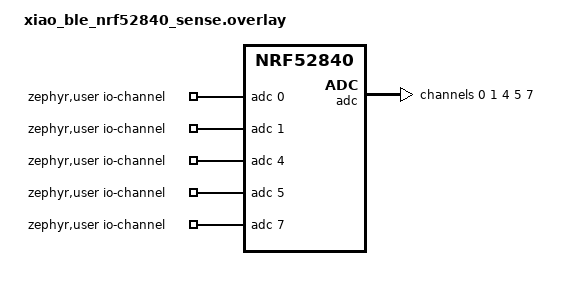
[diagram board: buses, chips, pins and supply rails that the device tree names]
/*
 * Copyright (c) 2025 NED KONZ <NED@METAMAGIX.TECH>
 *
 * SPDX-License-Identifier: Apache-2.0
 */

// Replace default on-chip flash with external flash
/delete-node/ &storage_partition;

// 16Mib (2MiB) flash, mount as /flash
&p25q16h {
	partitions {
		compatible = "fixed-partitions";
		#address-cells = <1>;
		#size-cells = <1>;

		storage_partition: partition@0 {
			label = "storage";
			reg = <0x00000000 0x200000>;
		};
	};
};

/ {
	zephyr,user {
		io-channels = <&adc 0>, <&adc 1>, <&adc 4>, <&adc 5>, <&adc 7>;
	};
};

&adc {
	#address-cells = <1>;
	#size-cells = <0>;

	channel@0 {
		reg = <0>;
		zephyr,gain = "ADC_GAIN_1_6";
		zephyr,reference = "ADC_REF_INTERNAL";
		zephyr,acquisition-time = <ADC_ACQ_TIME_DEFAULT>;
		zephyr,input-positive = <NRF_SAADC_AIN0>; /* P0.02 */
		zephyr,resolution = <12>;
	};

	channel@1 {
		reg = <1>;
		zephyr,gain = "ADC_GAIN_1_6";
		zephyr,reference = "ADC_REF_INTERNAL";
		zephyr,acquisition-time = <ADC_ACQ_TIME_DEFAULT>;
		zephyr,input-positive = <NRF_SAADC_AIN1>; /* P0.03 */
		zephyr,resolution = <12>;
	};

	channel@4 {
		reg = <4>;
		zephyr,gain = "ADC_GAIN_1_6";
		zephyr,reference = "ADC_REF_INTERNAL";
		zephyr,acquisition-time = <ADC_ACQ_TIME_DEFAULT>;
		zephyr,input-positive = <NRF_SAADC_AIN4>; /* P0.28 */
		zephyr,resolution = <12>;
	};

	channel@5 {
		reg = <5>;
		zephyr,gain = "ADC_GAIN_1_6";
		zephyr,reference = "ADC_REF_INTERNAL";
		zephyr,acquisition-time = <ADC_ACQ_TIME_DEFAULT>;
		zephyr,input-positive = <NRF_SAADC_AIN5>; /* P0.29 */
		zephyr,resolution = <12>;
	};

	// AIN7: battery reading
	channel@7 {
		reg = <7>;
		zephyr,gain = "ADC_GAIN_1_6";
		zephyr,reference = "ADC_REF_INTERNAL";
		zephyr,acquisition-time = <ADC_ACQ_TIME_DEFAULT>;
		zephyr,input-positive = <NRF_SAADC_AIN7>; /* P0.31 */
		zephyr,resolution = <12>;
	};
};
